# STM8AL3LE89 register map
Vendor: STMicroelectronics; Series: STM8L/STM8AL, high/medium+ density; File version: 1.0
CPU: other r1p0, big endian, no MPU, no FPU, 4 interrupt priority bits
Registers are 8-bit, read-write, reset 0x0 unless marked. A register's access mark holds for its fields unless they carry their own. Offsets are from the block's base; [hi:lo] are bit positions; {n}, {i} and the like mark numbered series.

## OPT
Base 0x00004800
0x00 OPT0 reset 0xAA — Read-out protection (ROP)
0x02 OPT1 — User boot code (UBC)
0x07 OPT2 — PCODESIZE
0x08 OPT3 — Watchdog option
0x09 OPT4 — Clock option
0x0A OPT5 reset 0x1 — Brownout reset (BOR)
0x0B OPTBL_H — Bootloader (high byte)
0x0C OPTBL_L — Bootloader (low byte)

## PWR
Base 0x000050B2
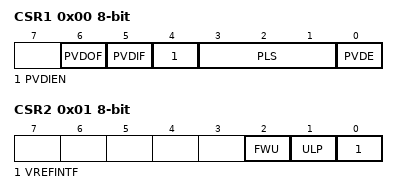
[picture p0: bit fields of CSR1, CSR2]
0x00 CSR1 — Power control and status register 1
  [6] PVDOF, [5] PVDIF, [4] PVDIEN, [3:1] PLS, [0] PVDE
0x01 CSR2 — Power control and status register 2
  [2] FWU, [1] ULP, [0] VREFINTF

## PORTA
Base 0x00005000
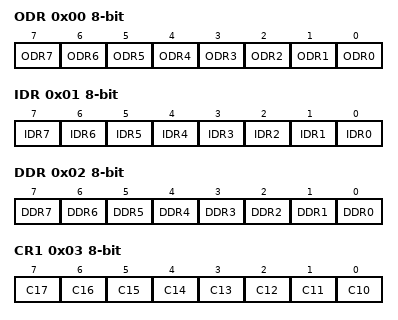
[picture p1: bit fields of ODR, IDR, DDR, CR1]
0x00 ODR — Port A data output latch register
  [n] ODR{n} (n=0..7)
0x01 IDR — Port A input pin value register
  [n] IDR{n} (n=0..7)
0x02 DDR — Port A data direction register
  [n] DDR{n} (n=0..7)
0x03 CR1 — Port A control register 1
  [n-10] C{n} (n=10..17)
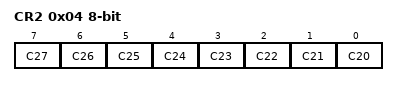
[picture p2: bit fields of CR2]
0x04 CR2 — Port A control register 2
  [n-20] C{n} (n=20..27)

## PORTB
Base 0x00005005
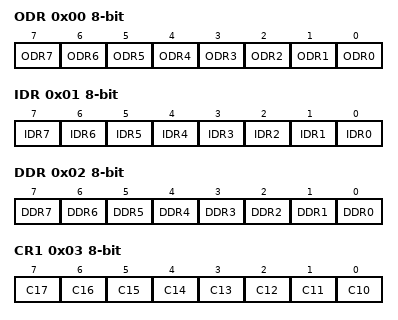
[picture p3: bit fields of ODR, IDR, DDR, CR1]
0x00 ODR — Port B data output latch register
  [n] ODR{n} (n=0..7)
0x01 IDR — Port B input pin value register
  [n] IDR{n} (n=0..7)
0x02 DDR — Port B data direction register
  [n] DDR{n} (n=0..7)
0x03 CR1 — Port B control register 1
  [n-10] C{n} (n=10..17)
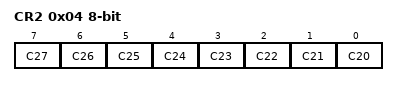
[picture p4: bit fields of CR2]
0x04 CR2 — Port B control register 2
  [n-20] C{n} (n=20..27)

## PORTC
Base 0x0000500A
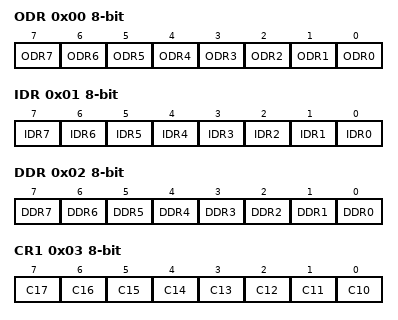
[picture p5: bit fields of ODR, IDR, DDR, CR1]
0x00 ODR — Port C data output latch register
  [n] ODR{n} (n=0..7)
0x01 IDR — Port C input pin value register
  [n] IDR{n} (n=0..7)
0x02 DDR — Port C data direction register
  [n] DDR{n} (n=0..7)
0x03 CR1 — Port C control register 1
  [n-10] C{n} (n=10..17)
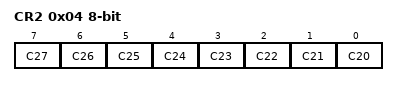
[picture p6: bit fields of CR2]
0x04 CR2 — Port C control register 2
  [n-20] C{n} (n=20..27)

## PORTD
Base 0x0000500F
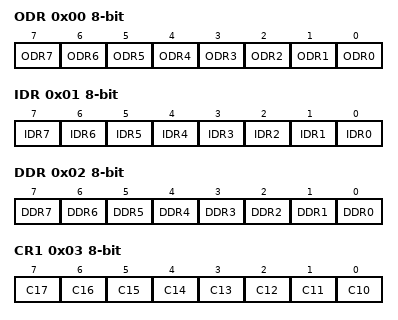
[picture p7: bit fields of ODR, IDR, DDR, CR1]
0x00 ODR — Port D data output latch register
  [n] ODR{n} (n=0..7)
0x01 IDR — Port D input pin value register
  [n] IDR{n} (n=0..7)
0x02 DDR — Port D data direction register
  [n] DDR{n} (n=0..7)
0x03 CR1 — Port D control register 1
  [n-10] C{n} (n=10..17)
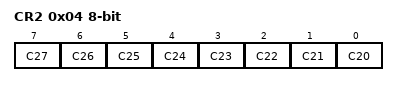
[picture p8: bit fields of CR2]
0x04 CR2 — Port D control register 2
  [n-20] C{n} (n=20..27)

## PORTE
Base 0x00005014
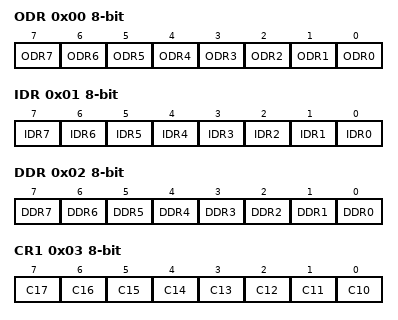
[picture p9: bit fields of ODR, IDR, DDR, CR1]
0x00 ODR — Port E data output latch register
  [n] ODR{n} (n=0..7)
0x01 IDR — Port E input pin value register
  [n] IDR{n} (n=0..7)
0x02 DDR — Port E data direction register
  [n] DDR{n} (n=0..7)
0x03 CR1 — Port E control register 1
  [n-10] C{n} (n=10..17)
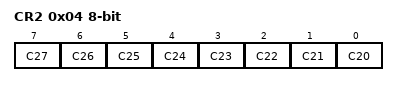
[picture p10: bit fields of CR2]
0x04 CR2 — Port E control register 2
  [n-20] C{n} (n=20..27)

## PORTF
Base 0x00005019
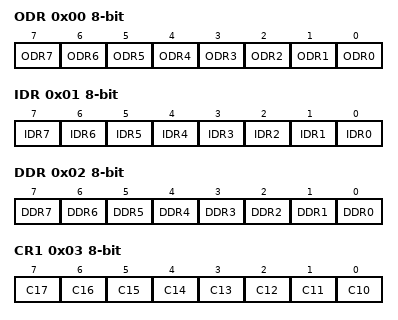
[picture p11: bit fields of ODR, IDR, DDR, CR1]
0x00 ODR — Port F data output latch register
  [n] ODR{n} (n=0..7)
0x01 IDR — Port F input pin value register
  [n] IDR{n} (n=0..7)
0x02 DDR — Port F data direction register
  [n] DDR{n} (n=0..7)
0x03 CR1 — Port F control register 1
  [n-10] C{n} (n=10..17)
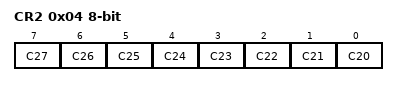
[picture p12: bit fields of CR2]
0x04 CR2 — Port F control register 2
  [n-20] C{n} (n=20..27)

## PORTG
Base 0x0000501E
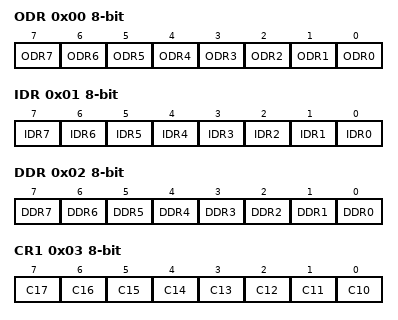
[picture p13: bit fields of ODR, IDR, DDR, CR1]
0x00 ODR — Port G data output latch register
  [n] ODR{n} (n=0..7)
0x01 IDR — Port G input pin value register
  [n] IDR{n} (n=0..7)
0x02 DDR — Port G data direction register
  [n] DDR{n} (n=0..7)
0x03 CR1 — Port G control register 1
  [n-10] C{n} (n=10..17)
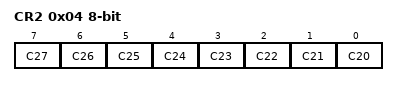
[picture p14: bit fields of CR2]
0x04 CR2 — Port G control register 2
  [n-20] C{n} (n=20..27)

## PORTH
Base 0x00005023
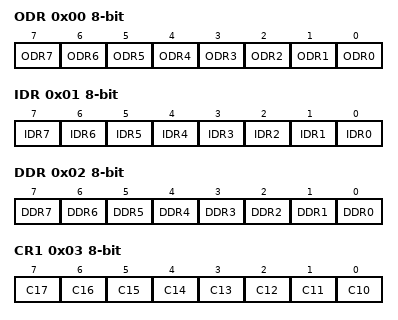
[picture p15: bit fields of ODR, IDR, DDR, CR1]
0x00 ODR — Port H data output latch register
  [n] ODR{n} (n=0..7)
0x01 IDR — Port H input pin value register
  [n] IDR{n} (n=0..7)
0x02 DDR — Port H data direction register
  [n] DDR{n} (n=0..7)
0x03 CR1 — Port H control register 1
  [n-10] C{n} (n=10..17)
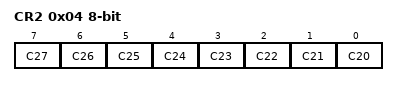
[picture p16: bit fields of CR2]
0x04 CR2 — Port H control register 2
  [n-20] C{n} (n=20..27)

## PORTI
Base 0x00005028
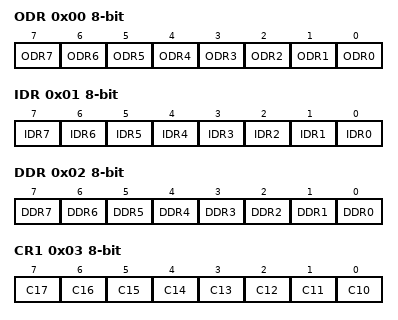
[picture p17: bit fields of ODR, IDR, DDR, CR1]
0x00 ODR — Port I data output latch register
  [n] ODR{n} (n=0..7)
0x01 IDR — Port I input pin value register
  [n] IDR{n} (n=0..7)
0x02 DDR — Port I data direction register
  [n] DDR{n} (n=0..7)
0x03 CR1 — Port I control register 1
  [n-10] C{n} (n=10..17)
0x04 CR2 — Port I control register 2
  [n-20] C{n} (n=20..27)
